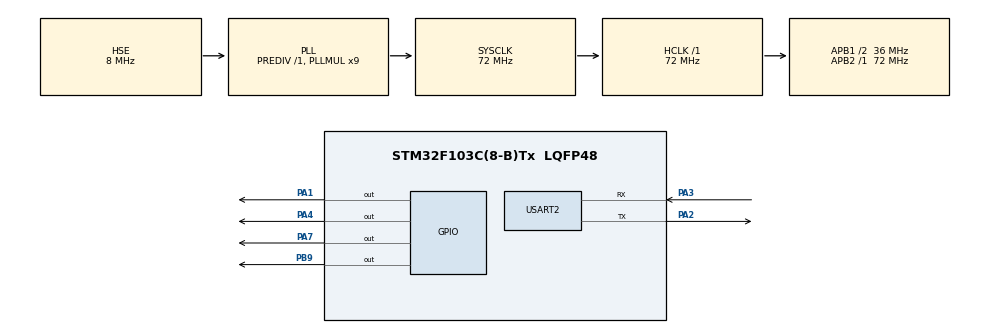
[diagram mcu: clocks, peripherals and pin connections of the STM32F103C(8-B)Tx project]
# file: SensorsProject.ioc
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Mcu.Family=STM32F1
Mcu.Name=STM32F103C(8-B)Tx
Mcu.Package=LQFP48
NVIC.PriorityGroup=NVIC_PRIORITYGROUP_4
PA1.Signal=GPIO_Output
PA2.Mode=Asynchronous
PA2.Signal=USART2_TX
PA3.Mode=Asynchronous
PA3.Signal=USART2_RX
PA4.Signal=GPIO_Output
PA7.Signal=GPIO_Output
PB9.Signal=GPIO_Output
PD0-OSC_IN.Mode=HSE-External-Oscillator
PD0-OSC_IN.Signal=RCC_OSC_IN
PD1-OSC_OUT.Mode=HSE-External-Oscillator
PD1-OSC_OUT.Signal=RCC_OSC_OUT
ProjectManager.HeapSize=0x200
ProjectManager.StackSize=0x400
ProjectManager.TargetToolchain=STM32CubeIDE
RCC.AHBFreq_Value=72000000
RCC.APB1CLKDivider=RCC_HCLK_DIV2
RCC.APB1Freq_Value=36000000
RCC.APB1TimFreq_Value=72000000
RCC.APB2Freq_Value=72000000
RCC.APB2TimFreq_Value=72000000
RCC.HCLKFreq_Value=72000000
RCC.PLLMUL=RCC_PLL_MUL9
RCC.PLLSourceVirtual=RCC_PLLSOURCE_HSE
RCC.SYSCLKFreq_VALUE=72000000
RCC.SYSCLKSource=RCC_SYSCLKSOURCE_PLLCLK
RCC.USBFreq_Value=72000000
TIM1.Prescaler=71
USART2.VirtualMode=VM_ASYNC
VP_TIM1_VS_ClockSourceINT.Mode=Internal
board=custom

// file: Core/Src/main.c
/* USER CODE BEGIN Header */
/**
  ******************************************************************************
  * @file           : main.c
  * @brief          : Main program body
  ******************************************************************************
  * @attention
  *
  * Copyright (c) 2025 STMicroelectronics.
  * All rights reserved.
  *
  * This software is licensed under terms that can be found in the LICENSE file
  * in the root directory of this software component.
  * If no LICENSE file comes with this software, it is provided AS-IS.
  *
  ******************************************************************************
  */
/* USER CODE END Header */
#include "main.h"
#include "tim.h"
#include "usart.h"
#include "gpio.h"

/* USER CODE BEGIN Includes */
#include "DHT11.h"
/* USER CODE END Includes */

void SystemClock_Config(void);

/* USER CODE BEGIN 0 */
//#define DHT11_PORT GPIOB
//#define DHT11_PIN GPIO_PIN_9
//uint8_t RHI, RHD, TCI, TCD, SUM;
//uint32_t pMillis, cMillis;
//float tCelsius = 0;
//float tFahrenheit = 0;
//float RH = 0;
//
//void microDelay (uint16_t delay)
//{
//  __HAL_TIM_SET_COUNTER(&htim1, 0);
//  while (__HAL_TIM_GET_COUNTER(&htim1) < delay);
//}
//
//uint8_t DHT11_Start (void)
//{
//  uint8_t Response = 0;
//  GPIO_InitTypeDef GPIO_InitStructPrivate = {0};
//  GPIO_InitStructPrivate.Pin = DHT11_PIN;
//  GPIO_InitStructPrivate.Mode = GPIO_MODE_OUTPUT_PP;
//  GPIO_InitStructPrivate.Speed = GPIO_SPEED_FREQ_LOW;
//  GPIO_InitStructPrivate.Pull = GPIO_NOPULL;
//  HAL_GPIO_Init(DHT11_PORT, &GPIO_InitStructPrivate); // set the pin as output
//  HAL_GPIO_WritePin (DHT11_PORT, DHT11_PIN, 0);   // pull the pin low
//  HAL_Delay(20);   // wait for 20ms
//  HAL_GPIO_WritePin (DHT11_PORT, DHT11_PIN, 1);   // pull the pin high
//  microDelay (30);   // wait for 30us
//  GPIO_InitStructPrivate.Mode = GPIO_MODE_INPUT;
//  GPIO_InitStructPrivate.Pull = GPIO_PULLUP;
//  HAL_GPIO_Init(DHT11_PORT, &GPIO_InitStructPrivate); // set the pin as input
//  microDelay (40);
//  if (!(HAL_GPIO_ReadPin (DHT11_PORT, DHT11_PIN)))
//  {
//    microDelay (80);
//    if ((HAL_GPIO_ReadPin (DHT11_PORT, DHT11_PIN))) Response = 1;
//  }
//  pMillis = HAL_GetTick();
//  cMillis = HAL_GetTick();
//  while ((HAL_GPIO_ReadPin (DHT11_PORT, DHT11_PIN)) && pMillis + 2 > cMillis)
//  {
//    cMillis = HAL_GetTick();
//  }
//  return Response;
//}
//
//uint8_t DHT11_Read (void)
//{
//  uint8_t a,b;
//  for (a=0;a<8;a++)
//  {
//    pMillis = HAL_GetTick();
//    cMillis = HAL_GetTick();
//    while (!(HAL_GPIO_ReadPin (DHT11_PORT, DHT11_PIN)) && pMillis + 2 > cMillis)
//    {  // wait for the pin to go high
//      cMillis = HAL_GetTick();
//    }
//    microDelay (40);   // wait for 40 us
//    if (!(HAL_GPIO_ReadPin (DHT11_PORT, DHT11_PIN)))   // if the pin is low
//      b&= ~(1<<(7-a));
//    else
//      b|= (1<<(7-a));
//    pMillis = HAL_GetTick();
//    cMillis = HAL_GetTick();
//    while ((HAL_GPIO_ReadPin (DHT11_PORT, DHT11_PIN)) && pMillis + 2 > cMillis)
//    {  // wait for the pin to go low
//      cMillis = HAL_GetTick();
//    }
//  }
//  return b;
//}

int __io_putchar(int ch)
{
    HAL_UART_Transmit(&huart2, (uint8_t*)&ch, 1, HAL_MAX_DELAY);
    return 1;
}
/* USER CODE END 0 */

int main(void)
{

  /* MCU Configuration--------------------------------------------------------*/

  /* Reset of all peripherals, Initializes the Flash interface and the Systick. */
  HAL_Init();

  /* Configure the system clock */
  SystemClock_Config();

  /* Initialize all configured peripherals */
  MX_GPIO_Init();
  MX_USART2_UART_Init();
  MX_TIM1_Init();
  /* USER CODE BEGIN 2 */
  HAL_TIM_Base_Start(&htim1);
  /* USER CODE END 2 */

  /* Infinite loop */
  /* USER CODE BEGIN WHILE */
//  float RHI = 0.0; // Relative humidity integral
//  float RHD = 0.0; // Relative humidity decimal
//  float SUM = 0.0; // Check sum
//  float RH = (float)RHI + (float)(RHD/10.0);

  while (1)
  {
//
//	  if(DHT11_Start())
//	     {
//	       RHI = DHT11_Read(); // Relative humidity integral
//	       RHD = DHT11_Read(); // Relative humidity decimal
////	       TCI = DHT11_Read(); // Celsius integral
////	       TCD = DHT11_Read(); // Celsius decimal
//	       SUM = DHT11_Read(); // Check sum
//	       if (RHI + RHD  == SUM)
//	       {
//	         // Can use RHI and TCI for any purposes if whole number only needed
////	         tCelsius = (float)TCI + (float)(TCD/10.0);
////	         tFahrenheit = tCelsius * 9/5 + 32;
//	         RH = (float)RHI + (float)(RHD/10.0);
//	         // Can use tCelsius, tFahrenheit and RH for any purposes
//	       }
//
//	     }
	  DHT11_ReadHumidity();
	  printf("____________________________________________________________________\r\n");
	  printf("Humidity: %.2f%%\r\n", RH);
	  HAL_Delay(2000);

    /* USER CODE END WHILE */

  }
}

void SystemClock_Config(void)
{
  RCC_OscInitTypeDef RCC_OscInitStruct = {0};
  RCC_ClkInitTypeDef RCC_ClkInitStruct = {0};

  /** Initializes the RCC Oscillators according to the specified parameters
  * in the RCC_OscInitTypeDef structure.
  */
  RCC_OscInitStruct.OscillatorType = RCC_OSCILLATORTYPE_HSE;
  RCC_OscInitStruct.HSEState = RCC_HSE_ON;
  RCC_OscInitStruct.HSEPredivValue = RCC_HSE_PREDIV_DIV1;
  RCC_OscInitStruct.HSIState = RCC_HSI_ON;
  RCC_OscInitStruct.PLL.PLLState = RCC_PLL_ON;
  RCC_OscInitStruct.PLL.PLLSource = RCC_PLLSOURCE_HSE;
  RCC_OscInitStruct.PLL.PLLMUL = RCC_PLL_MUL9;
  if (HAL_RCC_OscConfig(&RCC_OscInitStruct) != HAL_OK)
  {
    Error_Handler();
  }

  /** Initializes the CPU, AHB and APB buses clocks
  */
  RCC_ClkInitStruct.ClockType = RCC_CLOCKTYPE_HCLK|RCC_CLOCKTYPE_SYSCLK
                              |RCC_CLOCKTYPE_PCLK1|RCC_CLOCKTYPE_PCLK2;
  RCC_ClkInitStruct.SYSCLKSource = RCC_SYSCLKSOURCE_PLLCLK;
  RCC_ClkInitStruct.AHBCLKDivider = RCC_SYSCLK_DIV1;
  RCC_ClkInitStruct.APB1CLKDivider = RCC_HCLK_DIV2;
  RCC_ClkInitStruct.APB2CLKDivider = RCC_HCLK_DIV1;

  if (HAL_RCC_ClockConfig(&RCC_ClkInitStruct, FLASH_LATENCY_2) != HAL_OK)
  {
    Error_Handler();
  }
}

void Error_Handler(void)
{
  __disable_irq();
  while (1)
  {
  }
}
